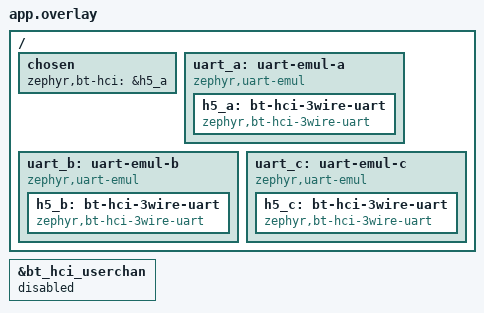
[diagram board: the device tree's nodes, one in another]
/*
 * SPDX-FileCopyrightText: Copyright (c) 2026 Silicon Laboratories Inc.
 * SPDX-License-Identifier: Apache-2.0
 */

/ {
	chosen {
		zephyr,bt-hci = &h5_a;
	};

	uart_a: uart-emul-a {
		compatible = "zephyr,uart-emul";
		status = "okay";

		h5_a: bt-hci-3wire-uart {
			compatible = "zephyr,bt-hci-3wire-uart";
			status = "okay";
		};
	};

	uart_b: uart-emul-b {
		compatible = "zephyr,uart-emul";
		status = "okay";

		h5_b: bt-hci-3wire-uart {
			compatible = "zephyr,bt-hci-3wire-uart";
			status = "okay";
		};
	};

	uart_c: uart-emul-c {
		compatible = "zephyr,uart-emul";
		status = "okay";

		h5_c: bt-hci-3wire-uart {
			compatible = "zephyr,bt-hci-3wire-uart";
			status = "okay";
		};
	};
};

&bt_hci_userchan {
	status = "disabled";
};
